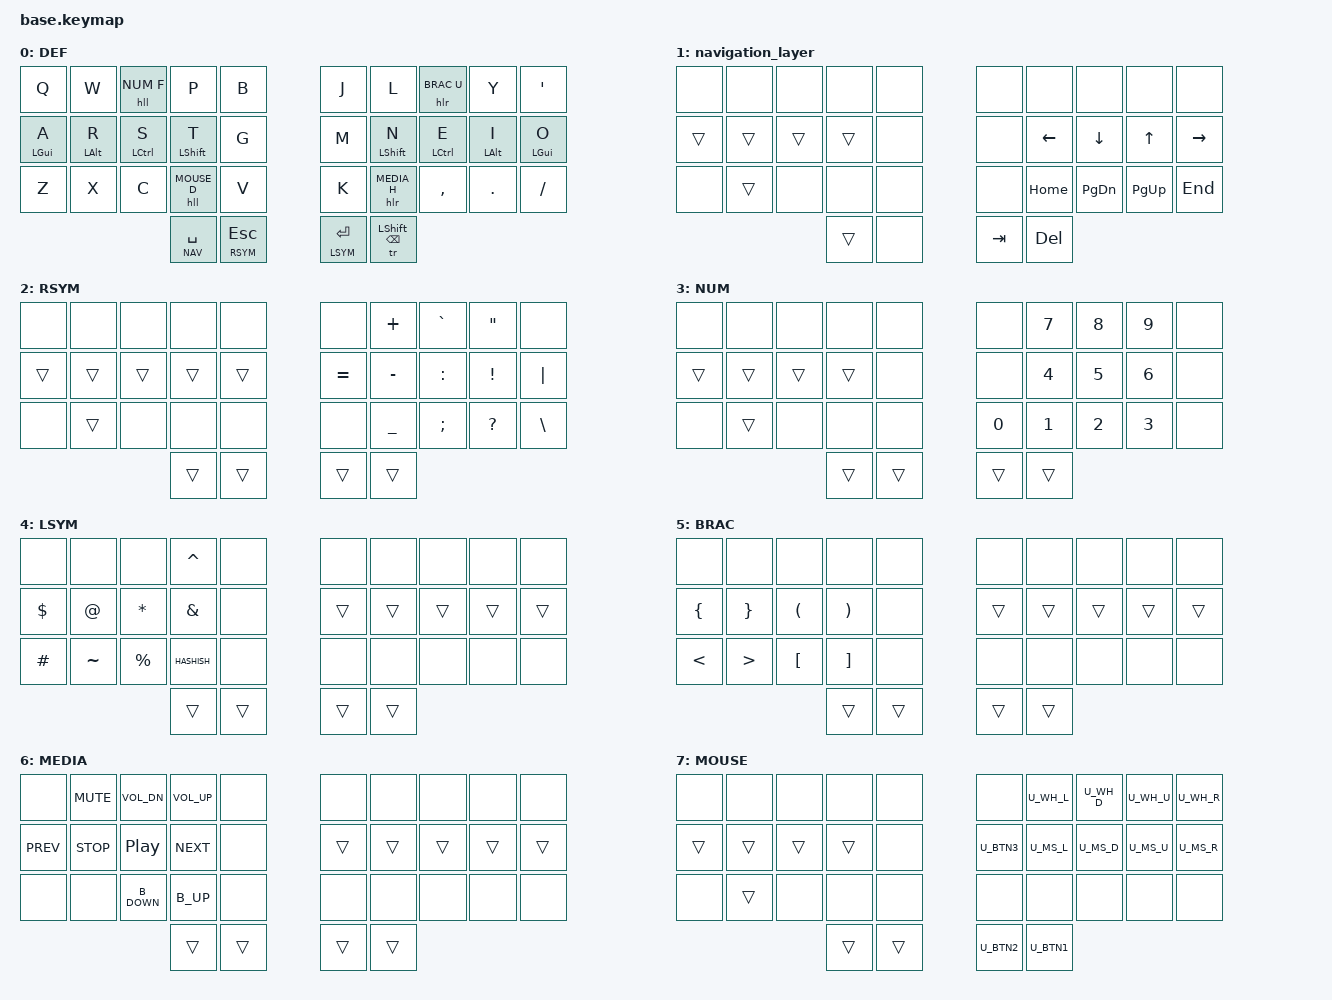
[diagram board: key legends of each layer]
#include <behaviors.dtsi>
#include <dt-bindings/zmk/keys.h>
#if CONFIG_WIRELESS
    #include <dt-bindings/zmk/bt.h>
    #define _BT_SEL_KEYS_ &bt BT_SEL 0 &bt BT_SEL 1 &bt BT_SEL 2 &bt BT_SEL 3 &bt BT_CLR
#else
    #define _BT_SEL_KEYS_ &trans &trans &trans &trans &trans
#endif


#include "../zmk-nodefree-config/helper.h"
#include "mouse.dtsi"

// Layer aliases
#define DEF 0 
#define NAV 1
#define RSYM 2
#define NUM 3
#define LSYM 4
#define BRAC 5
#define MEDIA 6 
#define MOUSE 7

#define HASHISH LA(N3) // Hash key on UK kb
#define B_UP LS(LA(LC(COMMA)))
#define B_DOWN LS(LA(LC(DOT)))
#define XXX &none
#define ___ &trans

/* Global settings */

#define QUICK_TAP_MS 175

&sk {  // sticky-key config
    release-after-ms = <900>;  // release after 0.6s
    quick-release;             // no double capitalization when rolling keys
};

&sl {  // sticky-layer config
    ignore-modifiers;          // allow chording sticky mods & layers
};

&lt {  // layer-tap config
    flavor = "balanced";
    tapping-term-ms = <200>;
    quick-tap-ms = <QUICK_TAP_MS>;
};

/* Homerow mods */

#define KEYS_L LT0 LT1 LT2 LT3 LT4 LM0 LM1 LM2 LM3 LM4 LB0 LB1 LB2 LB3 LB4  // left hand
#define KEYS_R RT0 RT1 RT2 RT3 RT4 RM0 RM1 RM2 RM3 RM4 RB0 RB1 RB2 RB3 RB4  // right hand
#define THUMBS LH1 LH0 RH0 RH1                                              // thumbs

#define MAKE_HRM(NAME, HOLD, TAP, TRIGGER_POS) \
    ZMK_BEHAVIOR(NAME, hold_tap, \
        flavor = "balanced"; \
        tapping-term-ms = <280>; \
        quick-tap-ms = <QUICK_TAP_MS>; \
        global-quick-tap-ms = <150>; \
        bindings = <HOLD>, <TAP>; \
        hold-trigger-key-positions = <TRIGGER_POS>; \
        hold-trigger-on-release; \
    )
MAKE_HRM(hml, &kp, &kp, KEYS_R THUMBS)  // left-hand HRMs
MAKE_HRM(hmr, &kp, &kp, KEYS_L THUMBS)  // right-hand HRMs

MAKE_HRM(hll, &mo, &kp, KEYS_R THUMBS)  // right-hand HRMs
MAKE_HRM(hlr, &mo, &kp, KEYS_L THUMBS)  // right-hand HRMs
MAKE_HRM(tr, &kp, &kp, KEYS_L)  // right-hand HRMs

// smart-mouse
ZMK_BEHAVIOR(smart_mouse, tri_state,
    bindings = <&tog MOUSE>, <&none>, <&tog MOUSE>;
    ignored-key-positions = <LT1 LT3 RT1 RT2 RT3 RM1 RM2 RM3 RH0 RH1>;
    ignored-layers = <MOUSE>;
)

// tap: space | shift + tap: dot -> space -> sticky shift | hold: activate layer
ZMK_BEHAVIOR(lt_spc, hold_tap,
    flavor = "balanced";
    tapping-term-ms = <200>;
    quick-tap-ms = <QUICK_TAP_MS>;
    bindings = <&mo>, <&spc_morph>;
)
ZMK_BEHAVIOR(spc_morph, mod_morph,
    bindings = <&kp SPACE>, <&dot_spc>;
    mods = <(MOD_LSFT|MOD_RSFT)>;
)
ZMK_BEHAVIOR(dot_spc, macro,
    wait-ms = <0>;
    tap-ms = <5>;
    bindings = <&kp DOT &kp SPACE &sk LSHFT>;
)

/ {
    keymap {
        compatible = "zmk,keymap";
        default_layer {
            label = "DEF";
            bindings = <
// ╭─────────────┬─────────────┬─────────────┬─────────────┬─────────────╮   ╭─────────────┬─────────────┬─────────────┬─────────────┬─────────────╮
     &kp Q         &kp W         &hll NUM F    &kp P         &kp B             &kp J         &kp L         &hlr BRAC U   &kp Y         &kp SQT
// ├─────────────┼─────────────┼─────────────┼─────────────┼─────────────┤   ├─────────────┼─────────────┼─────────────┼─────────────┼─────────────┤
     &hml LGUI A   &hml LALT R   &hml LCTRL S  &hml LSHFT T  &kp G             &kp M         &hmr LSHFT N  &hmr LCTRL E  &hmr LALT I   &hmr LGUI O
// ├─────────────┼─────────────┼─────────────┼─────────────┼─────────────┤   ├─────────────┼─────────────┼─────────────┼─────────────┼─────────────┤
     &kp Z         &kp X         &kp C         &hll MOUSE D  &kp V             &kp K         &hlr MEDIA H  &kp COMMA     &kp DOT       &kp SLASH
// ╰─────────────┴─────────────┴─────────────┼─────────────┼─────────────┤   ├─────────────┼─────────────┼─────────────┴─────────────┴─────────────╯
                                               &lt_spc NAV SPACE &lt RSYM ESC  &lt LSYM RET  &tr LSHFT BKSP
//                                           ╰─────────────┴─────────────╯   ╰─────────────┴─────────────╯
            >;
        };
        navigation_layer {
            bindings = <
// ╭─────────────┬─────────────┬─────────────┬─────────────┬─────────────╮   ╭─────────────┬─────────────┬─────────────┬─────────────┬─────────────╮
     XXX           XXX           XXX           XXX           XXX               XXX           XXX           XXX           XXX           XXX
// ├─────────────┼─────────────┼─────────────┼─────────────┼─────────────┤   ├─────────────┼─────────────┼─────────────┼─────────────┼─────────────┤
     ___           ___           ___           ___           XXX               XXX           &kp LEFT      &kp DOWN      &kp UP        &kp RIGHT
// ├─────────────┼─────────────┼─────────────┼─────────────┼─────────────┤   ├─────────────┼─────────────┼─────────────┼─────────────┼─────────────┤
     XXX           ___           XXX           XXX           XXX               XXX           &kp HOME      &kp PG_DN     &kp PG_UP     &kp END
// ╰─────────────┴─────────────┴─────────────┼─────────────┼─────────────┤   ├─────────────┼─────────────┼─────────────┴─────────────┴─────────────╯
                                               ___           XXX               &kp TAB       &kp DEL
//                                           ╰─────────────┴─────────────╯   ╰─────────────┴─────────────╯
            >;
        };
        right_symbol_layer {
            label = "RSYM";
            bindings = <
// ╭─────────────┬─────────────┬─────────────┬─────────────┬─────────────╮   ╭─────────────┬─────────────┬─────────────┬─────────────┬─────────────╮
     XXX           XXX           XXX           XXX           XXX               XXX           &kp PLUS      &kp GRAVE     &kp DQT       XXX 
// ├─────────────┼─────────────┼─────────────┼─────────────┼─────────────┤   ├─────────────┼─────────────┼─────────────┼─────────────┼─────────────┤
     ___           ___           ___           ___           ___               &kp EQUAL     &kp MINUS     &kp COLON     &kp EXCL      &kp PIPE
// ├─────────────┼─────────────┼─────────────┼─────────────┼─────────────┤   ├─────────────┼─────────────┼─────────────┼─────────────┼─────────────┤
     XXX           ___           XXX           XXX           XXX               XXX           &kp UNDER     &kp SEMI      &kp QMARK     &kp BSLH
// ╰─────────────┴─────────────┴─────────────┼─────────────┼─────────────┤   ├─────────────┼─────────────┼─────────────┴─────────────┴─────────────╯
                                                ___          ___               ___           ___
//                                           ╰─────────────┴─────────────╯   ╰─────────────┴─────────────╯
            >;
        };
        numbers_layer {
            label = "NUM";
            bindings = <
// ╭─────────────┬─────────────┬─────────────┬─────────────┬─────────────╮   ╭─────────────┬─────────────┬─────────────┬─────────────┬─────────────╮
     XXX           XXX           XXX           XXX           XXX               XXX           &kp N7        &kp N8        &kp N9        XXX 
// ├─────────────┼─────────────┼─────────────┼─────────────┼─────────────┤   ├─────────────┼─────────────┼─────────────┼─────────────┼─────────────┤
     ___           ___           ___           ___           XXX               XXX           &kp N4        &kp N5        &kp N6        XXX
// ├─────────────┼─────────────┼─────────────┼─────────────┼─────────────┤   ├─────────────┼─────────────┼─────────────┼─────────────┼─────────────┤
     XXX           ___           XXX           XXX           XXX               &kp N0        &kp N1        &kp N2        &kp N3        XXX
// ╰─────────────┴─────────────┴─────────────┼─────────────┼─────────────┤   ├─────────────┼─────────────┼─────────────┴─────────────┴─────────────╯
                                               ___           ___               ___           ___
//                                           ╰─────────────┴─────────────╯   ╰─────────────┴─────────────╯
            >;
        };
        left_symbols_layer {
            label = "LSYM";
            bindings = <
// ╭─────────────┬─────────────┬─────────────┬─────────────┬─────────────╮   ╭─────────────┬─────────────┬─────────────┬─────────────┬─────────────╮
     XXX           XXX           XXX           &kp CARET     XXX               XXX           XXX           XXX           XXX           XXX
// ├─────────────┼─────────────┼─────────────┼─────────────┼─────────────┤   ├─────────────┼─────────────┼─────────────┼─────────────┼─────────────┤
     &kp DLLR      &kp AT        &kp STAR      &kp AMPS      XXX               ___           ___           ___           ___           ___
// ├─────────────┼─────────────┼─────────────┼─────────────┼─────────────┤   ├─────────────┼─────────────┼─────────────┼─────────────┼─────────────┤
     &kp HASH      &kp TILDE     &kp PRCNT     &kp HASHISH   XXX               XXX           XXX           XXX           XXX           XXX
// ╰─────────────┴─────────────┴─────────────┼─────────────┼─────────────┤   ├─────────────┼─────────────┼─────────────┴─────────────┴─────────────╯
                                               ___           ___               ___           ___
//                                           ╰─────────────┴─────────────╯   ╰─────────────┴─────────────╯
            >;
        };
        brackets_layer {
            label = "BRAC";
            bindings = <
// ╭─────────────┬─────────────┬─────────────┬─────────────┬─────────────╮   ╭─────────────┬─────────────┬─────────────┬─────────────┬─────────────╮
     XXX           XXX           XXX           XXX           XXX               XXX           XXX           XXX           XXX           XXX
// ├─────────────┼─────────────┼─────────────┼─────────────┼─────────────┤   ├─────────────┼─────────────┼─────────────┼─────────────┼─────────────┤
     &kp LBRC      &kp RBRC      &kp LPAR      &kp RPAR      XXX               ___           ___           ___           ___           ___
// ├─────────────┼─────────────┼─────────────┼─────────────┼─────────────┤   ├─────────────┼─────────────┼─────────────┼─────────────┼─────────────┤
     &kp LT         &kp GT       &kp LBKT      &kp RBKT      XXX               XXX           XXX           XXX           XXX           XXX
// ╰─────────────┴─────────────┴─────────────┼─────────────┼─────────────┤   ├─────────────┼─────────────┼─────────────┴─────────────┴─────────────╯
                                               ___           ___               ___           ___
//                                           ╰─────────────┴─────────────╯   ╰─────────────┴─────────────╯
            >;
        };
        media_layer {
            label = "MEDIA";
            bindings = <
// ╭─────────────┬─────────────┬─────────────┬─────────────┬─────────────╮   ╭─────────────┬─────────────┬─────────────┬─────────────┬─────────────╮
     XXX           &kp K_MUTE    &kp C_VOL_DN  &kp C_VOL_UP  XXX               XXX           XXX           XXX           XXX           XXX
// ├─────────────┼─────────────┼─────────────┼─────────────┼─────────────┤   ├─────────────┼─────────────┼─────────────┼─────────────┼─────────────┤
     &kp C_PREV    &kp C_STOP    &kp C_PP      &kp C_NEXT    XXX               ___           ___           ___           ___           ___
// ├─────────────┼─────────────┼─────────────┼─────────────┼─────────────┤   ├─────────────┼─────────────┼─────────────┼─────────────┼─────────────┤
     XXX           XXX           &kp B_DOWN    &kp B_UP      XXX               XXX           XXX           XXX           XXX           XXX
// ╰─────────────┴─────────────┴─────────────┼─────────────┼─────────────┤   ├─────────────┼─────────────┼─────────────┴─────────────┴─────────────╯
                                               ___           ___               ___           ___
//                                           ╰─────────────┴─────────────╯   ╰─────────────┴─────────────╯
            >;
        };
        mouse_layer {
            label = "MOUSE";
            bindings = <
// ╭─────────────┬─────────────┬─────────────┬─────────────┬─────────────╮   ╭─────────────┬─────────────┬─────────────┬─────────────┬─────────────╮
     XXX           XXX           XXX           XXX           XXX               XXX           U_WH_L        U_WH_D        U_WH_U        U_WH_R 
// ├─────────────┼─────────────┼─────────────┼─────────────┼─────────────┤   ├─────────────┼─────────────┼─────────────┼─────────────┼─────────────┤
     ___           ___           ___           ___           XXX               U_BTN3        U_MS_L        U_MS_D        U_MS_U        U_MS_R
// ├─────────────┼─────────────┼─────────────┼─────────────┼─────────────┤   ├─────────────┼─────────────┼─────────────┼─────────────┼─────────────┤
     XXX           ___           XXX           XXX           XXX               XXX           XXX           XXX           XXX           XXX
// ╰─────────────┴─────────────┴─────────────┼─────────────┼─────────────┤   ├─────────────┼─────────────┼─────────────┴─────────────┴─────────────╯
                                               ___           ___               U_BTN2        U_BTN1
//                                           ╰─────────────┴─────────────╯   ╰─────────────┴─────────────╯
            >;
        };
    };
};
